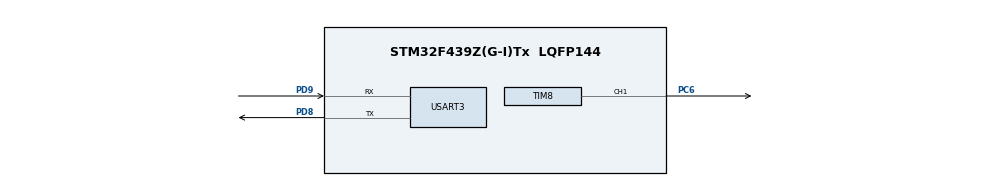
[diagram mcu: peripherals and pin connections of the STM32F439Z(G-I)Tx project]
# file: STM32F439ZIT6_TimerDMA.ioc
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Mcu.Family=STM32F4
Dma.TIM8_CH1.0.Direction=DMA_MEMORY_TO_PERIPH
RCC.CortexFreq_Value=16000000
TIM8.Pulse-PWM\ Generation1\ CH1=249
PC6.Signal=S_TIM8_CH1
PD9.Signal=USART3_RX
PD9.Mode=Asynchronous
Dma.TIM8_CH1.0.PeriphDataAlignment=DMA_PDATAALIGN_WORD
ProjectManager.StackSize=0x400
Dma.TIM8_CH1.0.Priority=DMA_PRIORITY_LOW
ProjectManager.TargetToolchain=STM32CubeIDE
TIM8.Channel-PWM\ Generation1\ CH1=TIM_CHANNEL_1
PD8.Signal=USART3_TX
Dma.TIM8_CH1.0.MemDataAlignment=DMA_MDATAALIGN_WORD
RCC.LSE_VALUE=32768
PD8.Mode=Asynchronous
RCC.AHBFreq_Value=16000000
RCC.HSE_VALUE=25000000
SH.S_TIM8_CH1.0=TIM8_CH1,PWM Generation1 CH1
board=custom
RCC.VCOOutputFreq_Value=192000000
Dma.TIM8_CH1.0.MemInc=DMA_MINC_ENABLE
RCC.APB2Freq_Value=16000000
Dma.TIM8_CH1.0.Mode=DMA_CIRCULAR
Dma.TIM8_CH1.0.Instance=DMA2_Stream2
Mcu.Name=STM32F439Z(G-I)Tx
TIM8.Period=799
RCC.SYSCLKFreq_VALUE=16000000
Mcu.Package=LQFP144
USART3.VirtualMode=VM_ASYNC
ProjectManager.HeapSize=0x200
Dma.TIM8_CH1.0.FIFOMode=DMA_FIFOMODE_DISABLE
RCC.HSI_VALUE=16000000
NVIC.PriorityGroup=NVIC_PRIORITYGROUP_4
NVIC.DMA2_Stream2_IRQn=true\:0\:0\:false\:false\:true\:false\:true
Dma.TIM8_CH1.0.PeriphInc=DMA_PINC_DISABLE
Dma.Request0=TIM8_CH1
RCC.APB1Freq_Value=16000000

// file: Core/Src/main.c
/* USER CODE BEGIN Header */
/**
  ******************************************************************************
  * @file           : main.c
  * @brief          : Main program body
  ******************************************************************************
  * @attention
  *
  * <h2><center>&copy; Copyright (c) 2023 STMicroelectronics.
  * All rights reserved.</center></h2>
  *
  * This software component is licensed by ST under BSD 3-Clause license,
  * the "License"; You may not use this file except in compliance with the
  * License. You may obtain a copy of the License at:
  *                        opensource.org/licenses/BSD-3-Clause
  *
  ******************************************************************************
  */
/* USER CODE END Header */
#include "main.h"

/* USER CODE BEGIN Includes */
#include <stdio.h>
#include <stdint.h>
#include <inttypes.h>
/* USER CODE END Includes */

/* USER CODE BEGIN PV */
static volatile uint32_t period_buffer[16];
/* USER CODE END PV */

void SystemClock_Config(void);
static void MX_GPIO_Init(void);
static void MX_DMA_Init(void);
static void MX_TIM8_Init(void);
static void MX_USART3_UART_Init(void);
/* USER CODE BEGIN PFP */
#ifdef __GNUC__
#define PUTCHAR_PROTOTYPE int __io_putchar(int ch)
#else
#define PUTCHAR_PROTOTYPE int fputc(int ch, FILE *f)
#endif

PUTCHAR_PROTOTYPE
{
  //HAL_UART_Transmit(&huart3, (uint8_t *)&ch, 1, HAL_MAX_DELAY);
  while (!LL_USART_IsActiveFlag_TXE(USART3));
  LL_USART_TransmitData8(USART3, ch);
  return ch;
}
/* USER CODE END PFP */

int main(void)
{

  /* MCU Configuration--------------------------------------------------------*/

  /* Reset of all peripherals, Initializes the Flash interface and the Systick. */

  LL_APB2_GRP1_EnableClock(LL_APB2_GRP1_PERIPH_SYSCFG);
  LL_APB1_GRP1_EnableClock(LL_APB1_GRP1_PERIPH_PWR);

  NVIC_SetPriorityGrouping(NVIC_PRIORITYGROUP_4);

  /* System interrupt init*/

  /* Configure the system clock */
  SystemClock_Config();

  /* Initialize all configured peripherals */
  MX_GPIO_Init();
  MX_DMA_Init();
  MX_TIM8_Init();
  MX_USART3_UART_Init();
  /* USER CODE BEGIN 2 */

  for (int i = 0; i < sizeof(period_buffer)/sizeof(period_buffer[0]); i++)
  {
	  period_buffer[i] = 500+i*200;
  }

  // timer channel 1 DMA
  {
    LL_DMA_ConfigAddresses(DMA2, LL_DMA_STREAM_2, (uint32_t)period_buffer, (uint32_t)&TIM8->ARR, LL_DMA_DIRECTION_MEMORY_TO_PERIPH);
    LL_DMA_SetDataLength(DMA2, LL_DMA_STREAM_2, sizeof(period_buffer)/sizeof(period_buffer[0]));
    LL_DMA_EnableStream(DMA2, LL_DMA_STREAM_2);
  }

  LL_TIM_EnableDMAReq_CC1(TIM8);
  LL_TIM_CC_EnableChannel(TIM8, LL_TIM_CHANNEL_CH1);
  LL_TIM_EnableAllOutputs(TIM8);
  LL_TIM_EnableCounter(TIM8);

  /*LL_GPIO_InitTypeDef GPIO_InitStruct = {0};
  GPIO_InitStruct.Pin = LL_GPIO_PIN_6;
  GPIO_InitStruct.Mode = LL_GPIO_MODE_OUTPUT;
  GPIO_InitStruct.Speed = LL_GPIO_SPEED_FREQ_VERY_HIGH;
  GPIO_InitStruct.OutputType = LL_GPIO_OUTPUT_PUSHPULL;
  GPIO_InitStruct.Pull = LL_GPIO_PULL_NO;
  LL_GPIO_Init(GPIOC, &GPIO_InitStruct);*/
  /* USER CODE END 2 */

  /* Infinite loop */
  while (1)
  {

    /* USER CODE BEGIN 3 */
	//LL_GPIO_SetOutputPin(GPIOC, LL_GPIO_PIN_6);
	static int i;
	const uint32_t cnt = LL_TIM_GetCounter(TIM8);
	printf("Hello World! CNT = %10" PRId32 "; time = %d\r\n", cnt, i);
	i++;
	//LL_GPIO_ResetOutputPin(GPIOC, LL_GPIO_PIN_6);

	LL_mDelay(50);
  }
  /* USER CODE END 3 */
}

void SystemClock_Config(void)
{
  LL_FLASH_SetLatency(LL_FLASH_LATENCY_0);
  while(LL_FLASH_GetLatency()!= LL_FLASH_LATENCY_0)
  {
  }
  LL_PWR_SetRegulVoltageScaling(LL_PWR_REGU_VOLTAGE_SCALE3);
  LL_PWR_DisableOverDriveMode();
  LL_RCC_HSI_SetCalibTrimming(16);
  LL_RCC_HSI_Enable();

   /* Wait till HSI is ready */
  while(LL_RCC_HSI_IsReady() != 1)
  {

  }
  LL_RCC_SetAHBPrescaler(LL_RCC_SYSCLK_DIV_1);
  LL_RCC_SetAPB1Prescaler(LL_RCC_APB1_DIV_1);
  LL_RCC_SetAPB2Prescaler(LL_RCC_APB2_DIV_1);
  LL_RCC_SetSysClkSource(LL_RCC_SYS_CLKSOURCE_HSI);

   /* Wait till System clock is ready */
  while(LL_RCC_GetSysClkSource() != LL_RCC_SYS_CLKSOURCE_STATUS_HSI)
  {

  }
  LL_Init1msTick(16000000);
  LL_SetSystemCoreClock(16000000);
  LL_RCC_SetTIMPrescaler(LL_RCC_TIM_PRESCALER_TWICE);
}

static void MX_TIM8_Init(void)
{

  LL_TIM_InitTypeDef TIM_InitStruct = {0};
  LL_TIM_OC_InitTypeDef TIM_OC_InitStruct = {0};
  LL_TIM_BDTR_InitTypeDef TIM_BDTRInitStruct = {0};

  LL_GPIO_InitTypeDef GPIO_InitStruct = {0};

  /* Peripheral clock enable */
  LL_APB2_GRP1_EnableClock(LL_APB2_GRP1_PERIPH_TIM8);

  /* TIM8 DMA Init */

  /* TIM8_CH1 Init */
  LL_DMA_SetChannelSelection(DMA2, LL_DMA_STREAM_2, LL_DMA_CHANNEL_7);

  LL_DMA_SetDataTransferDirection(DMA2, LL_DMA_STREAM_2, LL_DMA_DIRECTION_MEMORY_TO_PERIPH);

  LL_DMA_SetStreamPriorityLevel(DMA2, LL_DMA_STREAM_2, LL_DMA_PRIORITY_LOW);

  LL_DMA_SetMode(DMA2, LL_DMA_STREAM_2, LL_DMA_MODE_CIRCULAR);

  LL_DMA_SetPeriphIncMode(DMA2, LL_DMA_STREAM_2, LL_DMA_PERIPH_NOINCREMENT);

  LL_DMA_SetMemoryIncMode(DMA2, LL_DMA_STREAM_2, LL_DMA_MEMORY_INCREMENT);

  LL_DMA_SetPeriphSize(DMA2, LL_DMA_STREAM_2, LL_DMA_PDATAALIGN_WORD);

  LL_DMA_SetMemorySize(DMA2, LL_DMA_STREAM_2, LL_DMA_MDATAALIGN_WORD);

  LL_DMA_DisableFifoMode(DMA2, LL_DMA_STREAM_2);

  TIM_InitStruct.Prescaler = 0;
  TIM_InitStruct.CounterMode = LL_TIM_COUNTERMODE_UP;
  TIM_InitStruct.Autoreload = 799;
  TIM_InitStruct.ClockDivision = LL_TIM_CLOCKDIVISION_DIV1;
  TIM_InitStruct.RepetitionCounter = 0;
  LL_TIM_Init(TIM8, &TIM_InitStruct);
  LL_TIM_DisableARRPreload(TIM8);
  LL_TIM_OC_EnablePreload(TIM8, LL_TIM_CHANNEL_CH1);
  TIM_OC_InitStruct.OCMode = LL_TIM_OCMODE_PWM1;
  TIM_OC_InitStruct.OCState = LL_TIM_OCSTATE_DISABLE;
  TIM_OC_InitStruct.OCNState = LL_TIM_OCSTATE_DISABLE;
  TIM_OC_InitStruct.CompareValue = 249;
  TIM_OC_InitStruct.OCPolarity = LL_TIM_OCPOLARITY_HIGH;
  TIM_OC_InitStruct.OCNPolarity = LL_TIM_OCPOLARITY_HIGH;
  TIM_OC_InitStruct.OCIdleState = LL_TIM_OCIDLESTATE_LOW;
  TIM_OC_InitStruct.OCNIdleState = LL_TIM_OCIDLESTATE_LOW;
  LL_TIM_OC_Init(TIM8, LL_TIM_CHANNEL_CH1, &TIM_OC_InitStruct);
  LL_TIM_OC_DisableFast(TIM8, LL_TIM_CHANNEL_CH1);
  LL_TIM_SetTriggerOutput(TIM8, LL_TIM_TRGO_RESET);
  LL_TIM_DisableMasterSlaveMode(TIM8);
  TIM_BDTRInitStruct.OSSRState = LL_TIM_OSSR_DISABLE;
  TIM_BDTRInitStruct.OSSIState = LL_TIM_OSSI_DISABLE;
  TIM_BDTRInitStruct.LockLevel = LL_TIM_LOCKLEVEL_OFF;
  TIM_BDTRInitStruct.DeadTime = 0;
  TIM_BDTRInitStruct.BreakState = LL_TIM_BREAK_DISABLE;
  TIM_BDTRInitStruct.BreakPolarity = LL_TIM_BREAK_POLARITY_HIGH;
  TIM_BDTRInitStruct.AutomaticOutput = LL_TIM_AUTOMATICOUTPUT_DISABLE;
  LL_TIM_BDTR_Init(TIM8, &TIM_BDTRInitStruct);
  LL_AHB1_GRP1_EnableClock(LL_AHB1_GRP1_PERIPH_GPIOC);
  /**TIM8 GPIO Configuration
  PC6   ------> TIM8_CH1
  */
  GPIO_InitStruct.Pin = LL_GPIO_PIN_6;
  GPIO_InitStruct.Mode = LL_GPIO_MODE_ALTERNATE;
  GPIO_InitStruct.Speed = LL_GPIO_SPEED_FREQ_LOW;
  GPIO_InitStruct.OutputType = LL_GPIO_OUTPUT_PUSHPULL;
  GPIO_InitStruct.Pull = LL_GPIO_PULL_NO;
  GPIO_InitStruct.Alternate = LL_GPIO_AF_3;
  LL_GPIO_Init(GPIOC, &GPIO_InitStruct);

}

static void MX_USART3_UART_Init(void)
{

  LL_USART_InitTypeDef USART_InitStruct = {0};

  LL_GPIO_InitTypeDef GPIO_InitStruct = {0};

  /* Peripheral clock enable */
  LL_APB1_GRP1_EnableClock(LL_APB1_GRP1_PERIPH_USART3);

  LL_AHB1_GRP1_EnableClock(LL_AHB1_GRP1_PERIPH_GPIOD);
  /**USART3 GPIO Configuration
  PD8   ------> USART3_TX
  PD9   ------> USART3_RX
  */
  GPIO_InitStruct.Pin = LL_GPIO_PIN_8|LL_GPIO_PIN_9;
  GPIO_InitStruct.Mode = LL_GPIO_MODE_ALTERNATE;
  GPIO_InitStruct.Speed = LL_GPIO_SPEED_FREQ_VERY_HIGH;
  GPIO_InitStruct.OutputType = LL_GPIO_OUTPUT_PUSHPULL;
  GPIO_InitStruct.Pull = LL_GPIO_PULL_NO;
  GPIO_InitStruct.Alternate = LL_GPIO_AF_7;
  LL_GPIO_Init(GPIOD, &GPIO_InitStruct);

  USART_InitStruct.BaudRate = 115200;
  USART_InitStruct.DataWidth = LL_USART_DATAWIDTH_8B;
  USART_InitStruct.StopBits = LL_USART_STOPBITS_1;
  USART_InitStruct.Parity = LL_USART_PARITY_NONE;
  USART_InitStruct.TransferDirection = LL_USART_DIRECTION_TX_RX;
  USART_InitStruct.HardwareFlowControl = LL_USART_HWCONTROL_NONE;
  USART_InitStruct.OverSampling = LL_USART_OVERSAMPLING_16;
  LL_USART_Init(USART3, &USART_InitStruct);
  LL_USART_ConfigAsyncMode(USART3);
  LL_USART_Enable(USART3);

}

static void MX_DMA_Init(void)
{

  /* Init with LL driver */
  /* DMA controller clock enable */
  LL_AHB1_GRP1_EnableClock(LL_AHB1_GRP1_PERIPH_DMA2);

  /* DMA interrupt init */
  /* DMA2_Stream2_IRQn interrupt configuration */
  NVIC_SetPriority(DMA2_Stream2_IRQn, NVIC_EncodePriority(NVIC_GetPriorityGrouping(),0, 0));
  NVIC_EnableIRQ(DMA2_Stream2_IRQn);

}

static void MX_GPIO_Init(void)
{

  /* GPIO Ports Clock Enable */
  LL_AHB1_GRP1_EnableClock(LL_AHB1_GRP1_PERIPH_GPIOD);
  LL_AHB1_GRP1_EnableClock(LL_AHB1_GRP1_PERIPH_GPIOC);

}

void Error_Handler(void)
{
  __disable_irq();
  while (1)
  {
  }
}

/************************ (C) COPYRIGHT STMicroelectronics *****END OF FILE****/
